# COMPUTE_CLUSTER_J7AHP0_DRU_0_MMR_DRU4_MMR_CFG_DRU_CHNRT register map
Vendor: Texas Instruments
Peripheral module from a debugger description file (folder J7_AHP).
Registers are 64-bit, read-write, reset 0x0 unless marked. A register's access mark holds for its fields unless they carry their own. Offsets are as the file gives them; lines under a group give offsets from that group; [hi:lo] are bit positions; {n}, {i} and the like mark numbered series; 'fields as' and 'values as' point back to an identical list; <NAME> marks a mode.

## COMPUTE_CLUSTER_J7AHP0_DRU_0_MMR_DRU4_MMR_CFG_DRU_CHNRT
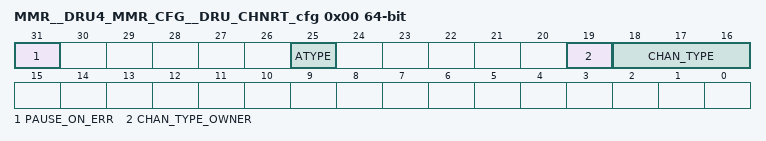
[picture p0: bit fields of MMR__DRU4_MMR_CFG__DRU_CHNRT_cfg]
0x00 MMR__DRU4_MMR_CFG__DRU_CHNRT_cfg access per field
  [31] PAUSE_ON_ERR rw — Pause on Error. This field controls what the channel will do if an error or exception occurs during a data transfer. This field is encoded as follows: 0 = Channel will drop current work and move on 1 = Channel will pause and wait for SW to investigate and un-pause the channel.
  [25] ATYPE rw — Address type. This field controls how the pointers are interpreted for TRs on this channel. This field is encoded as follows: 0 = Pointers are physical addresses 1 = Pointers are virtual addresses which require virtual to physical translation before they can be decoded.
  [19] CHAN_TYPE_OWNER rw — This field controls how the TR is received by the UTC. If it is 0 then the SUBMISSION registers must be written to submit it. If it is a 1 then the TR will be received through PSIL.
  [18:16] CHAN_TYPE ro — This field states the TR type that is being used it along with CHAN_TYPE_OWNER field make up the 4 bit CHAN_TYPE for a KS3 DMA UTC. The value of this is all zeroes. To reflect that the UTC DRU only does TRs through pass by value mechanisms.
0x20 MMR__DRU4_MMR_CFG__DRU_CHNRT_choes0
  [15:0] EVT_NUM — This is the global event number to be generated.
0x60 MMR__DRU4_MMR_CFG__DRU_CHNRT_chst_sched
  [2:0] QUEUE — This is the queue number that is written
